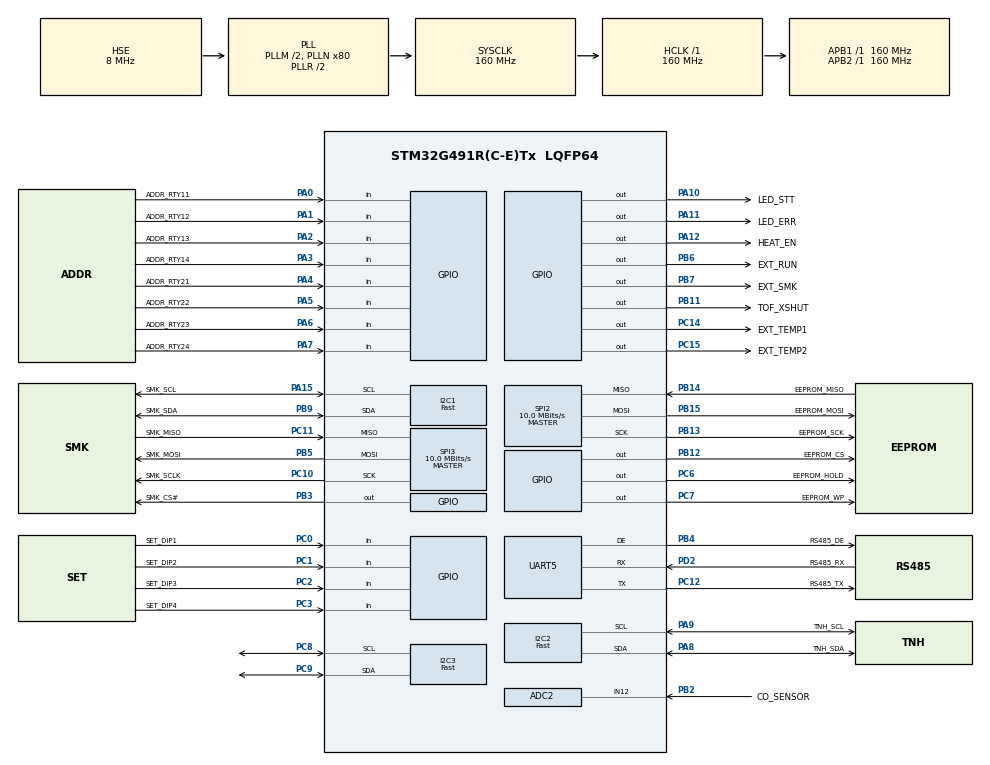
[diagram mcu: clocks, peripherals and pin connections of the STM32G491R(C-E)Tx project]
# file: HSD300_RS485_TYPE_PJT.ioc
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ADC2.Channel-0\#ChannelRegularConversion=ADC_CHANNEL_12
ADC2.ClockPrescaler=ADC_CLOCK_ASYNC_DIV4
ADC2.ContinuousConvMode=ENABLE
ADC2.DMAContinuousRequests=ENABLE
ADC2.NbrOfConversionFlag=1
ADC2.OffsetNumber-0\#ChannelRegularConversion=ADC_OFFSET_NONE
ADC2.Rank-0\#ChannelRegularConversion=1
ADC2.SamplingTime-0\#ChannelRegularConversion=ADC_SAMPLETIME_24CYCLES_5
Dma.ADC2.0.Direction=DMA_PERIPH_TO_MEMORY
Dma.ADC2.0.EventEnable=DISABLE
Dma.ADC2.0.Instance=DMA1_Channel1
Dma.ADC2.0.MemDataAlignment=DMA_MDATAALIGN_HALFWORD
Dma.ADC2.0.MemInc=DMA_MINC_ENABLE
Dma.ADC2.0.Mode=DMA_CIRCULAR
Dma.ADC2.0.PeriphDataAlignment=DMA_PDATAALIGN_HALFWORD
Dma.ADC2.0.PeriphInc=DMA_PINC_DISABLE
Dma.ADC2.0.Polarity=HAL_DMAMUX_REQ_GEN_RISING
Dma.ADC2.0.Priority=DMA_PRIORITY_HIGH
Dma.ADC2.0.RequestNumber=1
Dma.ADC2.0.SignalID=NONE
Dma.ADC2.0.SyncEnable=DISABLE
Dma.ADC2.0.SyncPolarity=HAL_DMAMUX_SYNC_NO_EVENT
Dma.ADC2.0.SyncRequestNumber=1
Dma.ADC2.0.SyncSignalID=NONE
Dma.Request0=ADC2
I2C1.I2C_Speed_Mode=I2C_Fast
I2C1.Timing=0x00F07BFF
I2C2.I2C_Speed_Mode=I2C_Fast
I2C2.Timing=0x00F07BFF
I2C3.I2C_Speed_Mode=I2C_Fast
I2C3.Timing=0x00F07BFF
Mcu.Family=STM32G4
Mcu.Name=STM32G491R(C-E)Tx
Mcu.Package=LQFP64
NVIC.ADC1_2_IRQn=true\:5\:0\:true\:false\:true\:true\:true\:true
NVIC.DMA1_Channel1_IRQn=true\:5\:0\:true\:false\:true\:false\:true\:true
NVIC.PriorityGroup=NVIC_PRIORITYGROUP_4
NVIC.SPI3_IRQn=true\:0\:0\:false\:false\:true\:true\:true\:true
NVIC.TIM6_DAC_IRQn=true\:5\:0\:true\:false\:true\:true\:true\:true
NVIC.UART5_IRQn=true\:5\:0\:true\:false\:true\:true\:true\:true
PA0.GPIO_Label=ADDR_RTY11
PA0.Signal=GPIO_Input
PA1.GPIO_Label=ADDR_RTY12
PA1.Signal=GPIO_Input
PA10.GPIO_Label=LED_STT
PA10.PinState=GPIO_PIN_SET
PA10.Signal=GPIO_Output
PA11.GPIO_Label=LED_ERR
PA11.PinState=GPIO_PIN_SET
PA11.Signal=GPIO_Output
PA12.GPIO_Label=HEAT_EN
PA12.Signal=GPIO_Output
PA13.Mode=Serial_Wire
PA13.Signal=SYS_JTMS-SWDIO
PA14.Mode=Serial_Wire
PA14.Signal=SYS_JTCK-SWCLK
PA15.GPIO_Label=SMK_SCL
PA15.GPIO_Mode=GPIO_MODE_AF_OD
PA15.GPIO_Pu=GPIO_PULLUP
PA15.Mode=I2C
PA15.Signal=I2C1_SCL
PA2.GPIO_Label=ADDR_RTY13
PA2.Signal=GPIO_Input
PA3.GPIO_Label=ADDR_RTY14
PA3.Signal=GPIO_Input
PA4.GPIO_Label=ADDR_RTY21
PA4.Signal=GPIO_Input
PA5.GPIO_Label=ADDR_RTY22
PA5.Signal=GPIO_Input
PA6.GPIO_Label=ADDR_RTY23
PA6.Signal=GPIO_Input
PA7.GPIO_Label=ADDR_RTY24
PA7.Signal=GPIO_Input
PA8.GPIO_Label=TNH_SDA
PA8.GPIO_Pu=GPIO_PULLUP
PA8.Mode=I2C
PA8.Signal=I2C2_SDA
PA9.GPIO_Label=TNH_SCL
PA9.GPIO_Pu=GPIO_PULLUP
PA9.Mode=I2C
PA9.Signal=I2C2_SCL
PB11.GPIO_Label=TOF_XSHUT
PB11.Signal=GPIO_Output
PB12.GPIO_Label=EEPROM_CS
PB12.Signal=GPIO_Output
PB13.GPIO_Label=EEPROM_SCK
PB13.Mode=Full_Duplex_Master
PB13.Signal=SPI2_SCK
PB14.GPIO_Label=EEPROM_MISO
PB14.Mode=Full_Duplex_Master
PB14.Signal=SPI2_MISO
PB15.GPIO_Label=EEPROM_MOSI
PB15.Mode=Full_Duplex_Master
PB15.Signal=SPI2_MOSI
PB2.GPIO_Label=CO_SENSOR
PB2.Mode=IN12-Single-Ended
PB2.Signal=ADC2_IN12
PB3.GPIO_Label=SMK_CS\#
PB3.PinState=GPIO_PIN_SET
PB3.Signal=GPIO_Output
PB4.GPIO_Label=RS485_DE
PB4.Mode=Hardware Flow Control (RS485)
PB4.Signal=UART5_DE
PB5.GPIO_Label=SMK_MOSI
PB5.Mode=Full_Duplex_Master
PB5.Signal=SPI3_MOSI
PB6.GPIO_Label=EXT_RUN
PB6.Signal=GPIO_Output
PB7.GPIO_Label=EXT_SMK
PB7.Signal=GPIO_Output
PB9.GPIO_FM9=SYSCFG_FASTMODEPLUS_PB9
PB9.GPIO_Label=SMK_SDA
PB9.GPIO_Pu=GPIO_PULLUP
PB9.Mode=I2C
PB9.Signal=I2C1_SDA
PC0.GPIO_Label=SET_DIP1
PC0.Signal=GPIO_Input
PC1.GPIO_Label=SET_DIP2
PC1.Signal=GPIO_Input
PC10.GPIO_Label=SMK_SCLK
PC10.Mode=Full_Duplex_Master
PC10.Signal=SPI3_SCK
PC11.GPIO_Label=SMK_MISO
PC11.Mode=Full_Duplex_Master
PC11.Signal=SPI3_MISO
PC12.GPIO_Label=RS485_TX
PC12.Mode=Asynchronous
PC12.Signal=UART5_TX
PC14-OSC32_IN.GPIO_Label=EXT_TEMP1
PC14-OSC32_IN.Signal=GPIO_Output
PC15-OSC32_OUT.GPIO_Label=EXT_TEMP2
PC15-OSC32_OUT.Signal=GPIO_Output
PC2.GPIO_Label=SET_DIP3
PC2.Signal=GPIO_Input
PC3.GPIO_Label=SET_DIP4
PC3.Signal=GPIO_Input
PC6.GPIO_Label=EEPROM_HOLD
PC6.PinState=GPIO_PIN_SET
PC6.Signal=GPIO_Output
PC7.GPIO_Label=EEPROM_WP
PC7.PinState=GPIO_PIN_SET
PC7.Signal=GPIO_Output
PC8.GPIO_Pu=GPIO_PULLUP
PC8.Mode=I2C
PC8.Signal=I2C3_SCL
PC9.GPIO_Pu=GPIO_PULLUP
PC9.Mode=I2C
PC9.Signal=I2C3_SDA
PD2.GPIO_Label=RS485_RX
PD2.Mode=Asynchronous
PD2.Signal=UART5_RX
PF0-OSC_IN.Mode=HSE-External-Oscillator
PF0-OSC_IN.Signal=RCC_OSC_IN
PF1-OSC_OUT.Mode=HSE-External-Oscillator
PF1-OSC_OUT.Signal=RCC_OSC_OUT
ProjectManager.HeapSize=0x200
ProjectManager.StackSize=0x400
ProjectManager.TargetToolchain=STM32CubeIDE
RCC.ADC12CLockSelection=RCC_ADC12CLKSOURCE_PLL
RCC.ADC12Freq_Value=160000000
RCC.ADC345Freq_Value=160000000
RCC.AHBFreq_Value=160000000
RCC.APB1Freq_Value=160000000
RCC.APB1TimFreq_Value=160000000
RCC.APB2Freq_Value=160000000
RCC.APB2TimFreq_Value=160000000
RCC.CortexFreq_Value=160000000
RCC.EXTERNAL_CLOCK_VALUE=12288000
RCC.HCLKFreq_Value=160000000
RCC.HSE_VALUE=8000000
RCC.HSI48_VALUE=48000000
RCC.HSI_VALUE=16000000
RCC.LSE_VALUE=32768
RCC.PLLM=RCC_PLLM_DIV2
RCC.PLLN=80
RCC.PLLSourceVirtual=RCC_PLLSOURCE_HSE
RCC.SYSCLKFreq_VALUE=160000000
RCC.SYSCLKSource=RCC_SYSCLKSOURCE_PLLCLK
RCC.USBFreq_Value=48000000
RCC.VCOOutputFreq_Value=320000000
SPI2.BaudRatePrescaler=SPI_BAUDRATEPRESCALER_16
SPI2.CLKPhase=SPI_PHASE_1EDGE
SPI2.CLKPolarity=SPI_POLARITY_LOW
SPI2.CalculateBaudRate=10.0 MBits/s
SPI2.Direction=SPI_DIRECTION_2LINES
SPI2.Mode=SPI_MODE_MASTER
SPI2.VirtualType=VM_MASTER
SPI3.BaudRatePrescaler=SPI_BAUDRATEPRESCALER_16
SPI3.CLKPhase=SPI_PHASE_2EDGE
SPI3.CLKPolarity=SPI_POLARITY_HIGH
SPI3.CalculateBaudRate=10.0 MBits/s
SPI3.Direction=SPI_DIRECTION_2LINES
SPI3.Mode=SPI_MODE_MASTER
SPI3.VirtualType=VM_MASTER
STMicroelectronics.X-CUBE-TOF1.3.3.1.TOF_RANGING_MODE=Polling
TIM6.PeriodNoDither=1000-1
TIM6.Prescaler=160-1
UART5.OverrunDisableParam=UART_ADVFEATURE_OVERRUN_ENABLE
VP_SYS_VS_DBSignals.Mode=DisableDeadBatterySignals
VP_TIM6_VS_ClockSourceINT.Mode=Enable_Timer
board=custom

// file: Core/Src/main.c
/* USER CODE BEGIN Header */
/**
  ******************************************************************************
  * @file           : main.c
  * @brief          : Main program body
  ******************************************************************************
  * @attention
  *
  * Copyright (c) 2023 STMicroelectronics.
  * All rights reserved.
  *
  * This software is licensed under terms that can be found in the LICENSE file
  * in the root directory of this software component.
  * If no LICENSE file comes with this software, it is provided AS-IS.
  *
  ******************************************************************************
  */
/* USER CODE END Header */
#include "main.h"

/* USER CODE BEGIN Includes */
#include "..\Source\HSD300_FW.h"
/* USER CODE END Includes */

ADC_HandleTypeDef hadc2;
DMA_HandleTypeDef hdma_adc2;

I2C_HandleTypeDef hi2c1;
I2C_HandleTypeDef hi2c2;
I2C_HandleTypeDef hi2c3;

SPI_HandleTypeDef hspi2;
SPI_HandleTypeDef hspi3;

TIM_HandleTypeDef htim6;

UART_HandleTypeDef huart5;

void SystemClock_Config(void);
static void MX_GPIO_Init(void);
static void MX_DMA_Init(void);
static void MX_ADC2_Init(void);
static void MX_I2C1_Init(void);
static void MX_I2C2_Init(void);
static void MX_SPI3_Init(void);
static void MX_UART5_Init(void);
static void MX_TIM6_Init(void);
static void MX_I2C3_Init(void);
static void MX_SPI2_Init(void);

int main(void)
{
  /* USER CODE BEGIN 1 */
	SCB->VTOR = 0x8008000;  //매우 중요 Vector Table Offset Register

  /* USER CODE END 1 */

  /* MCU Configuration--------------------------------------------------------*/

  /* Reset of all peripherals, Initializes the Flash interface and the Systick. */
  HAL_Init();

  /* Configure the system clock */
  SystemClock_Config();

  /* Initialize all configured peripherals */
  MX_GPIO_Init();
  MX_DMA_Init();
  MX_ADC2_Init();
  MX_I2C1_Init();
  MX_I2C2_Init();
  MX_SPI3_Init();
  MX_UART5_Init();
  MX_TIM6_Init();
  MX_I2C3_Init();
  MX_SPI2_Init();
  /* USER CODE BEGIN 2 */
  //HAL_Delay(250);
  FUN_bootloader_init();
  FUN_TIM_init();
  EEPROM_init();
  RS485_Init();
  FUN_ADC_Init(&hadc2);
  FUN_I2C_SHT30_Init();
  Gas_Sensor_Init();
  //FUN_I2C_VL53L3CX_Init();

  /* USER CODE END 2 */

  /* Infinite loop */
  /* USER CODE BEGIN WHILE */
  while (1)
   {
	Task_Schedule_freerun();
    /* USER CODE END WHILE */

    /* USER CODE BEGIN 3 */
	FUN_bootloader_freerun();
  }
  /* USER CODE END 3 */
}

void SystemClock_Config(void)
{
  RCC_OscInitTypeDef RCC_OscInitStruct = {0};
  RCC_ClkInitTypeDef RCC_ClkInitStruct = {0};

  /** Configure the main internal regulator output voltage
  */
  HAL_PWREx_ControlVoltageScaling(PWR_REGULATOR_VOLTAGE_SCALE1_BOOST);

  /** Initializes the RCC Oscillators according to the specified parameters
  * in the RCC_OscInitTypeDef structure.
  */
  RCC_OscInitStruct.OscillatorType = RCC_OSCILLATORTYPE_HSE;
  RCC_OscInitStruct.HSEState = RCC_HSE_ON;
  RCC_OscInitStruct.PLL.PLLState = RCC_PLL_ON;
  RCC_OscInitStruct.PLL.PLLSource = RCC_PLLSOURCE_HSE;
  RCC_OscInitStruct.PLL.PLLM = RCC_PLLM_DIV2;
  RCC_OscInitStruct.PLL.PLLN = 80;
  RCC_OscInitStruct.PLL.PLLP = RCC_PLLP_DIV2;
  RCC_OscInitStruct.PLL.PLLQ = RCC_PLLQ_DIV2;
  RCC_OscInitStruct.PLL.PLLR = RCC_PLLR_DIV2;
  if (HAL_RCC_OscConfig(&RCC_OscInitStruct) != HAL_OK)
  {
    Error_Handler();
  }

  /** Initializes the CPU, AHB and APB buses clocks
  */
  RCC_ClkInitStruct.ClockType = RCC_CLOCKTYPE_HCLK|RCC_CLOCKTYPE_SYSCLK
                              |RCC_CLOCKTYPE_PCLK1|RCC_CLOCKTYPE_PCLK2;
  RCC_ClkInitStruct.SYSCLKSource = RCC_SYSCLKSOURCE_PLLCLK;
  RCC_ClkInitStruct.AHBCLKDivider = RCC_SYSCLK_DIV1;
  RCC_ClkInitStruct.APB1CLKDivider = RCC_HCLK_DIV1;
  RCC_ClkInitStruct.APB2CLKDivider = RCC_HCLK_DIV1;

  if (HAL_RCC_ClockConfig(&RCC_ClkInitStruct, FLASH_LATENCY_4) != HAL_OK)
  {
    Error_Handler();
  }
}

static void MX_ADC2_Init(void)
{

  ADC_ChannelConfTypeDef sConfig = {0};

  /** Common config
  */
  hadc2.Instance = ADC2;
  hadc2.Init.ClockPrescaler = ADC_CLOCK_ASYNC_DIV4;
  hadc2.Init.Resolution = ADC_RESOLUTION_12B;
  hadc2.Init.DataAlign = ADC_DATAALIGN_RIGHT;
  hadc2.Init.GainCompensation = 0;
  hadc2.Init.ScanConvMode = ADC_SCAN_DISABLE;
  hadc2.Init.EOCSelection = ADC_EOC_SINGLE_CONV;
  hadc2.Init.LowPowerAutoWait = DISABLE;
  hadc2.Init.ContinuousConvMode = ENABLE;
  hadc2.Init.NbrOfConversion = 1;
  hadc2.Init.DiscontinuousConvMode = DISABLE;
  hadc2.Init.ExternalTrigConv = ADC_SOFTWARE_START;
  hadc2.Init.ExternalTrigConvEdge = ADC_EXTERNALTRIGCONVEDGE_NONE;
  hadc2.Init.DMAContinuousRequests = ENABLE;
  hadc2.Init.Overrun = ADC_OVR_DATA_PRESERVED;
  hadc2.Init.OversamplingMode = DISABLE;
  if (HAL_ADC_Init(&hadc2) != HAL_OK)
  {
    Error_Handler();
  }

  /** Configure Regular Channel
  */
  sConfig.Channel = ADC_CHANNEL_12;
  sConfig.Rank = ADC_REGULAR_RANK_1;
  sConfig.SamplingTime = ADC_SAMPLETIME_24CYCLES_5;
  sConfig.SingleDiff = ADC_SINGLE_ENDED;
  sConfig.OffsetNumber = ADC_OFFSET_NONE;
  sConfig.Offset = 0;
  if (HAL_ADC_ConfigChannel(&hadc2, &sConfig) != HAL_OK)
  {
    Error_Handler();
  }

}

static void MX_I2C1_Init(void)
{

  hi2c1.Instance = I2C1;
  hi2c1.Init.Timing = 0x00F07BFF;
  hi2c1.Init.OwnAddress1 = 0;
  hi2c1.Init.AddressingMode = I2C_ADDRESSINGMODE_7BIT;
  hi2c1.Init.DualAddressMode = I2C_DUALADDRESS_DISABLE;
  hi2c1.Init.OwnAddress2 = 0;
  hi2c1.Init.OwnAddress2Masks = I2C_OA2_NOMASK;
  hi2c1.Init.GeneralCallMode = I2C_GENERALCALL_DISABLE;
  hi2c1.Init.NoStretchMode = I2C_NOSTRETCH_DISABLE;
  if (HAL_I2C_Init(&hi2c1) != HAL_OK)
  {
    Error_Handler();
  }

  /** Configure Analogue filter
  */
  if (HAL_I2CEx_ConfigAnalogFilter(&hi2c1, I2C_ANALOGFILTER_ENABLE) != HAL_OK)
  {
    Error_Handler();
  }

  /** Configure Digital filter
  */
  if (HAL_I2CEx_ConfigDigitalFilter(&hi2c1, 0) != HAL_OK)
  {
    Error_Handler();
  }

}

static void MX_I2C2_Init(void)
{

  hi2c2.Instance = I2C2;
  hi2c2.Init.Timing = 0x00F07BFF;
  hi2c2.Init.OwnAddress1 = 0;
  hi2c2.Init.AddressingMode = I2C_ADDRESSINGMODE_7BIT;
  hi2c2.Init.DualAddressMode = I2C_DUALADDRESS_DISABLE;
  hi2c2.Init.OwnAddress2 = 0;
  hi2c2.Init.OwnAddress2Masks = I2C_OA2_NOMASK;
  hi2c2.Init.GeneralCallMode = I2C_GENERALCALL_DISABLE;
  hi2c2.Init.NoStretchMode = I2C_NOSTRETCH_DISABLE;
  if (HAL_I2C_Init(&hi2c2) != HAL_OK)
  {
    Error_Handler();
  }

  /** Configure Analogue filter
  */
  if (HAL_I2CEx_ConfigAnalogFilter(&hi2c2, I2C_ANALOGFILTER_ENABLE) != HAL_OK)
  {
    Error_Handler();
  }

  /** Configure Digital filter
  */
  if (HAL_I2CEx_ConfigDigitalFilter(&hi2c2, 0) != HAL_OK)
  {
    Error_Handler();
  }

}

static void MX_I2C3_Init(void)
{

  hi2c3.Instance = I2C3;
  hi2c3.Init.Timing = 0x00F07BFF;
  hi2c3.Init.OwnAddress1 = 0;
  hi2c3.Init.AddressingMode = I2C_ADDRESSINGMODE_7BIT;
  hi2c3.Init.DualAddressMode = I2C_DUALADDRESS_DISABLE;
  hi2c3.Init.OwnAddress2 = 0;
  hi2c3.Init.OwnAddress2Masks = I2C_OA2_NOMASK;
  hi2c3.Init.GeneralCallMode = I2C_GENERALCALL_DISABLE;
  hi2c3.Init.NoStretchMode = I2C_NOSTRETCH_DISABLE;
  if (HAL_I2C_Init(&hi2c3) != HAL_OK)
  {
    Error_Handler();
  }

  /** Configure Analogue filter
  */
  if (HAL_I2CEx_ConfigAnalogFilter(&hi2c3, I2C_ANALOGFILTER_ENABLE) != HAL_OK)
  {
    Error_Handler();
  }

  /** Configure Digital filter
  */
  if (HAL_I2CEx_ConfigDigitalFilter(&hi2c3, 0) != HAL_OK)
  {
    Error_Handler();
  }

}

static void MX_SPI2_Init(void)
{

  /* SPI2 parameter configuration*/
  hspi2.Instance = SPI2;
  hspi2.Init.Mode = SPI_MODE_MASTER;
  hspi2.Init.Direction = SPI_DIRECTION_2LINES;
  hspi2.Init.DataSize = SPI_DATASIZE_8BIT;
  hspi2.Init.CLKPolarity = SPI_POLARITY_LOW;
  hspi2.Init.CLKPhase = SPI_PHASE_1EDGE;
  hspi2.Init.NSS = SPI_NSS_SOFT;
  hspi2.Init.BaudRatePrescaler = SPI_BAUDRATEPRESCALER_16;
  hspi2.Init.FirstBit = SPI_FIRSTBIT_MSB;
  hspi2.Init.TIMode = SPI_TIMODE_DISABLE;
  hspi2.Init.CRCCalculation = SPI_CRCCALCULATION_DISABLE;
  hspi2.Init.CRCPolynomial = 7;
  hspi2.Init.CRCLength = SPI_CRC_LENGTH_DATASIZE;
  hspi2.Init.NSSPMode = SPI_NSS_PULSE_ENABLE;
  if (HAL_SPI_Init(&hspi2) != HAL_OK)
  {
    Error_Handler();
  }

}

static void MX_SPI3_Init(void)
{

  /* SPI3 parameter configuration*/
  hspi3.Instance = SPI3;
  hspi3.Init.Mode = SPI_MODE_MASTER;
  hspi3.Init.Direction = SPI_DIRECTION_2LINES;
  hspi3.Init.DataSize = SPI_DATASIZE_8BIT;
  hspi3.Init.CLKPolarity = SPI_POLARITY_HIGH;
  hspi3.Init.CLKPhase = SPI_PHASE_2EDGE;
  hspi3.Init.NSS = SPI_NSS_SOFT;
  hspi3.Init.BaudRatePrescaler = SPI_BAUDRATEPRESCALER_16;
  hspi3.Init.FirstBit = SPI_FIRSTBIT_MSB;
  hspi3.Init.TIMode = SPI_TIMODE_DISABLE;
  hspi3.Init.CRCCalculation = SPI_CRCCALCULATION_DISABLE;
  hspi3.Init.CRCPolynomial = 7;
  hspi3.Init.CRCLength = SPI_CRC_LENGTH_DATASIZE;
  hspi3.Init.NSSPMode = SPI_NSS_PULSE_DISABLE;
  if (HAL_SPI_Init(&hspi3) != HAL_OK)
  {
    Error_Handler();
  }

}

static void MX_TIM6_Init(void)
{

  TIM_MasterConfigTypeDef sMasterConfig = {0};

  htim6.Instance = TIM6;
  htim6.Init.Prescaler = 160-1;
  htim6.Init.CounterMode = TIM_COUNTERMODE_UP;
  htim6.Init.Period = 999;
  htim6.Init.AutoReloadPreload = TIM_AUTORELOAD_PRELOAD_DISABLE;
  if (HAL_TIM_Base_Init(&htim6) != HAL_OK)
  {
    Error_Handler();
  }
  sMasterConfig.MasterOutputTrigger = TIM_TRGO_RESET;
  sMasterConfig.MasterSlaveMode = TIM_MASTERSLAVEMODE_DISABLE;
  if (HAL_TIMEx_MasterConfigSynchronization(&htim6, &sMasterConfig) != HAL_OK)
  {
    Error_Handler();
  }

}

static void MX_UART5_Init(void)
{

  huart5.Instance = UART5;
  huart5.Init.BaudRate = 115200;
  huart5.Init.WordLength = UART_WORDLENGTH_8B;
  huart5.Init.StopBits = UART_STOPBITS_1;
  huart5.Init.Parity = UART_PARITY_NONE;
  huart5.Init.Mode = UART_MODE_TX_RX;
  huart5.Init.HwFlowCtl = UART_HWCONTROL_NONE;
  huart5.Init.OverSampling = UART_OVERSAMPLING_16;
  huart5.Init.OneBitSampling = UART_ONE_BIT_SAMPLE_DISABLE;
  huart5.Init.ClockPrescaler = UART_PRESCALER_DIV1;
  huart5.AdvancedInit.AdvFeatureInit = UART_ADVFEATURE_NO_INIT;
  if (HAL_RS485Ex_Init(&huart5, UART_DE_POLARITY_HIGH, 0, 0) != HAL_OK)
  {
    Error_Handler();
  }
  if (HAL_UARTEx_SetTxFifoThreshold(&huart5, UART_TXFIFO_THRESHOLD_1_8) != HAL_OK)
  {
    Error_Handler();
  }
  if (HAL_UARTEx_SetRxFifoThreshold(&huart5, UART_RXFIFO_THRESHOLD_1_8) != HAL_OK)
  {
    Error_Handler();
  }
  if (HAL_UARTEx_DisableFifoMode(&huart5) != HAL_OK)
  {
    Error_Handler();
  }

}

static void MX_DMA_Init(void)
{

  /* DMA controller clock enable */
  __HAL_RCC_DMAMUX1_CLK_ENABLE();
  __HAL_RCC_DMA1_CLK_ENABLE();

  /* DMA interrupt init */
  /* DMA1_Channel1_IRQn interrupt configuration */
  HAL_NVIC_SetPriority(DMA1_Channel1_IRQn, 5, 0);
  HAL_NVIC_EnableIRQ(DMA1_Channel1_IRQn);

}

static void MX_GPIO_Init(void)
{
  GPIO_InitTypeDef GPIO_InitStruct = {0};

  /* GPIO Ports Clock Enable */
  __HAL_RCC_GPIOC_CLK_ENABLE();
  __HAL_RCC_GPIOF_CLK_ENABLE();
  __HAL_RCC_GPIOA_CLK_ENABLE();
  __HAL_RCC_GPIOB_CLK_ENABLE();
  __HAL_RCC_GPIOD_CLK_ENABLE();

  /*Configure GPIO pin Output Level */
  HAL_GPIO_WritePin(GPIOC, EXT_TEMP1_Pin|EXT_TEMP2_Pin, GPIO_PIN_RESET);

  /*Configure GPIO pin Output Level */
  HAL_GPIO_WritePin(GPIOB, TOF_XSHUT_Pin|EEPROM_CS_Pin|EXT_RUN_Pin|EXT_SMK_Pin, GPIO_PIN_RESET);

  /*Configure GPIO pin Output Level */
  HAL_GPIO_WritePin(GPIOC, EEPROM_HOLD_Pin|EEPROM_WP_Pin, GPIO_PIN_SET);

  /*Configure GPIO pin Output Level */
  HAL_GPIO_WritePin(GPIOA, LED_STT_Pin|LED_ERR_Pin, GPIO_PIN_SET);

  /*Configure GPIO pin Output Level */
  HAL_GPIO_WritePin(HEAT_EN_GPIO_Port, HEAT_EN_Pin, GPIO_PIN_RESET);

  /*Configure GPIO pin Output Level */
  HAL_GPIO_WritePin(SMK_CS__GPIO_Port, SMK_CS__Pin, GPIO_PIN_SET);

  /*Configure GPIO pins : EXT_TEMP1_Pin EXT_TEMP2_Pin EEPROM_HOLD_Pin EEPROM_WP_Pin */
  GPIO_InitStruct.Pin = EXT_TEMP1_Pin|EXT_TEMP2_Pin|EEPROM_HOLD_Pin|EEPROM_WP_Pin;
  GPIO_InitStruct.Mode = GPIO_MODE_OUTPUT_PP;
  GPIO_InitStruct.Pull = GPIO_NOPULL;
  GPIO_InitStruct.Speed = GPIO_SPEED_FREQ_LOW;
  HAL_GPIO_Init(GPIOC, &GPIO_InitStruct);

  /*Configure GPIO pins : SET_DIP1_Pin SET_DIP2_Pin SET_DIP3_Pin SET_DIP4_Pin */
  GPIO_InitStruct.Pin = SET_DIP1_Pin|SET_DIP2_Pin|SET_DIP3_Pin|SET_DIP4_Pin;
  GPIO_InitStruct.Mode = GPIO_MODE_INPUT;
  GPIO_InitStruct.Pull = GPIO_NOPULL;
  HAL_GPIO_Init(GPIOC, &GPIO_InitStruct);

  /*Configure GPIO pins : ADDR_RTY11_Pin ADDR_RTY12_Pin ADDR_RTY13_Pin ADDR_RTY14_Pin
                           ADDR_RTY21_Pin ADDR_RTY22_Pin ADDR_RTY23_Pin ADDR_RTY24_Pin */
  GPIO_InitStruct.Pin = ADDR_RTY11_Pin|ADDR_RTY12_Pin|ADDR_RTY13_Pin|ADDR_RTY14_Pin
                          |ADDR_RTY21_Pin|ADDR_RTY22_Pin|ADDR_RTY23_Pin|ADDR_RTY24_Pin;
  GPIO_InitStruct.Mode = GPIO_MODE_INPUT;
  GPIO_InitStruct.Pull = GPIO_NOPULL;
  HAL_GPIO_Init(GPIOA, &GPIO_InitStruct);

  /*Configure GPIO pins : TOF_XSHUT_Pin EEPROM_CS_Pin SMK_CS__Pin EXT_RUN_Pin
                           EXT_SMK_Pin */
  GPIO_InitStruct.Pin = TOF_XSHUT_Pin|EEPROM_CS_Pin|SMK_CS__Pin|EXT_RUN_Pin
                          |EXT_SMK_Pin;
  GPIO_InitStruct.Mode = GPIO_MODE_OUTPUT_PP;
  GPIO_InitStruct.Pull = GPIO_NOPULL;
  GPIO_InitStruct.Speed = GPIO_SPEED_FREQ_LOW;
  HAL_GPIO_Init(GPIOB, &GPIO_InitStruct);

  /*Configure GPIO pins : LED_STT_Pin LED_ERR_Pin HEAT_EN_Pin */
  GPIO_InitStruct.Pin = LED_STT_Pin|LED_ERR_Pin|HEAT_EN_Pin;
  GPIO_InitStruct.Mode = GPIO_MODE_OUTPUT_PP;
  GPIO_InitStruct.Pull = GPIO_NOPULL;
  GPIO_InitStruct.Speed = GPIO_SPEED_FREQ_LOW;
  HAL_GPIO_Init(GPIOA, &GPIO_InitStruct);

}

void Error_Handler(void)
{
  __disable_irq();
  while (1)
  {
  }
}
